# MB9BF51xN register map
File version: 1.8
CPU: 
Registers are 8-bit, read-write, reset 0x0 unless marked. A register's access mark holds for its fields unless they carry their own. Offsets are from the block's base; [hi:lo] are bit positions; {n}, {i} and the like mark numbered series.

## GPIO — General-purpose I/O ports
Base 0x40033000
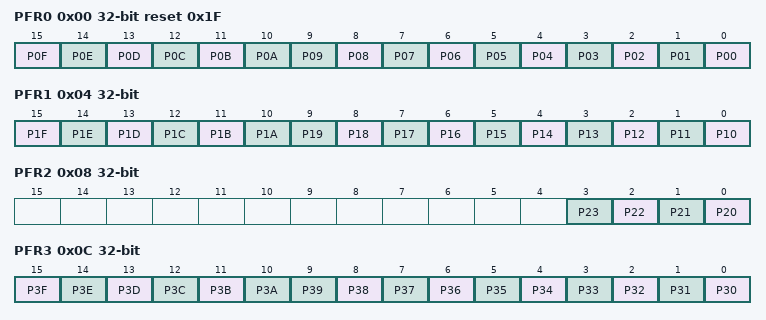
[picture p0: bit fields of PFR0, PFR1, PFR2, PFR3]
0x00 PFR0 32-bit reset 0x1F — Port function setting register 0
  [15] P0F — Bit15 of PFR0
  [14] P0E — Bit14 of PFR0
  [13] P0D — Bit13 of PFR0
  [12] P0C — Bit12 of PFR0
  [11] P0B — Bit11 of PFR0
  [10] P0A — Bit10 of PFR0
  [n] P{n:02} (n=0..9) — Bit{n} of PFR0
0x04 PFR1 32-bit — Port function setting register 1
  [15] P1F — Bit15 of PFR1
  [14] P1E — Bit14 of PFR1
  [13] P1D — Bit13 of PFR1
  [12] P1C — Bit12 of PFR1
  [11] P1B — Bit11 of PFR1
  [10] P1A — Bit10 of PFR1
  [n-10] P{n} (n=10..19) — Bit{n-10} of PFR1
0x08 PFR2 32-bit — Port function setting register 2
  [n-20] P{n} (n=20..23) — Bit{n-20} of PFR2
0x0C PFR3 32-bit — Port function setting register 3
  [15] P3F — Bit15 of PFR3
  [14] P3E — Bit14 of PFR3
  [13] P3D — Bit13 of PFR3
  [12] P3C — Bit12 of PFR3
  [11] P3B — Bit11 of PFR3
  [10] P3A — Bit10 of PFR3
  [n-30] P{n} (n=30..39) — Bit{n-30} of PFR3
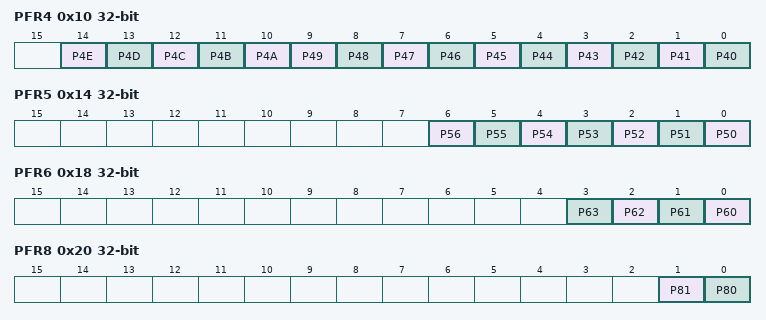
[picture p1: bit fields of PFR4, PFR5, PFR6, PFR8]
0x10 PFR4 32-bit — Port function setting register 4
  [14] P4E — Bit14 of PFR4
  [13] P4D — Bit13 of PFR4
  [12] P4C — Bit12 of PFR4
  [11] P4B — Bit11 of PFR4
  [10] P4A — Bit10 of PFR4
  [n-40] P{n} (n=40..49) — Bit{n-40} of PFR4
0x14 PFR5 32-bit — Port function setting register 5
  [n-50] P{n} (n=50..56) — Bit{n-50} of PFR5
0x18 PFR6 32-bit — Port function setting register 6
  [n-60] P{n} (n=60..63) — Bit{n-60} of PFR6
0x20 PFR8 32-bit — Port function setting register 8
  [1] P81 — Bit1 of PFR8
  [0] P80 — Bit0 of PFR8
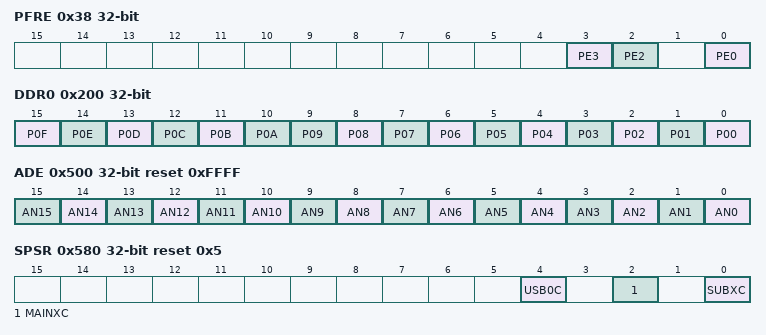
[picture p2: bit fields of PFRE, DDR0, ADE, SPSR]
0x38 PFRE 32-bit (reset mask 0xB) — Port function setting register E
  [3] PE3 — Bit3 of PFRE
  [2] PE2 — Bit2 of PFRE
  [0] PE0 — Bit0 of PFRE
{0x100+4i} PCR{i} 32-bit reset not defined (i=0..6) — Pull-up Setting Register {i}
0x120 PCR8 32-bit reset not defined — Pull-up Setting Register 8
0x138 PCRE 32-bit reset not defined — Pull-up Setting Register E
0x200 DDR0 32-bit — Port input/output direction setting register 0
  [15] P0F — Bit15 of DDR0
  [14] P0E — Bit14 of DDR0
  [13] P0D — Bit13 of DDR0
  [12] P0C — Bit12 of DDR0
  [11] P0B — Bit11 of DDR0
  [10] P0A — Bit10 of DDR0
  [n] P{n:02} (n=0..9) — Bit{n} of DDR0
{0x200+4i} DDR{i} 32-bit reset not defined (i=1..6) — Port input/output direction setting register {i}
0x220 DDR8 32-bit reset not defined — Port input/output direction setting register 8
0x238 DDRE 32-bit reset not defined — Port input/output direction setting register E
{0x300+4i} PDIR{i} 32-bit reset not defined (i=0..6) — Port input data register {i}
0x320 PDIR8 32-bit reset not defined — Port input data register 8
0x338 PDIRE 32-bit reset not defined — Port input data register E
{0x400+4i} PDOR{i} 32-bit reset not defined (i=0..6) — Port output data register {i}
0x420 PDOR8 32-bit reset not defined — Port output data register 8
0x438 PDORE 32-bit reset not defined — Port output data register E
0x500 ADE 32-bit reset 0xFFFF — Analog input setting register
  [n] AN{n} (n=0..15) — Bit{n} of ADE
0x580 SPSR 32-bit reset 0x5 — Special port setting register
  [4] USB0C — USBch0 pin setting bit
  [2] MAINXC — Main clock(oscillation) pin setting bit
  [0] SUBXC — Sub clock(oscillation) pin setting bit
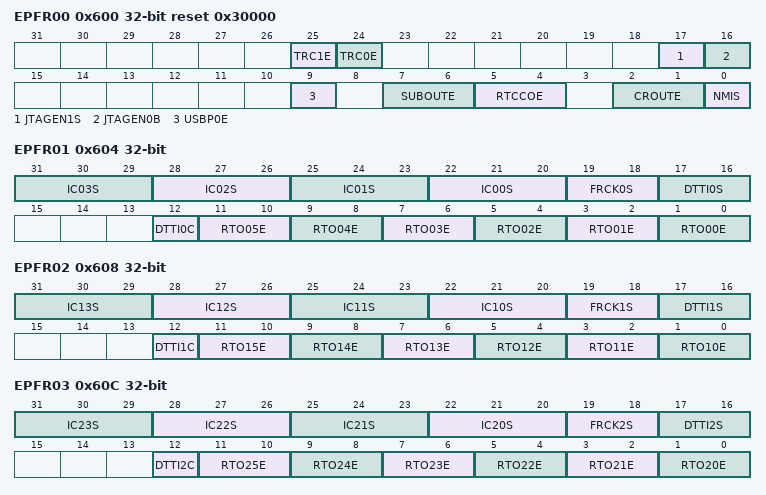
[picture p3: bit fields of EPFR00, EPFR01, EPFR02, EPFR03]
0x600 EPFR00 32-bit reset 0x30000 — Extended pin function setting register 00
  [25] TRC1E — TRACED function select bit1
  [24] TRC0E — TRACED function select bit0
  [17] JTAGEN1S — JTAG function select bit1
  [16] JTAGEN0B — JTAG function select bit0
  [9] USBP0E — USBch0 function select bit
  [7:6] SUBOUTE — Sub clock divide output function select bit
  [5:4] RTCCOE — RTC clock output select bit
  [2:1] CROUTE — Internal high-speed CR oscillation output function select bit
  [0] NMIS — NMIX function select bit
0x604 EPFR01 32-bit — Extended pin function setting register 01
  [3n+22:3n+20] IC{n:02}S (n=0..3) — IC{n:02} input select bit
  [19:18] FRCK0S — FRCK0 input select bit
  [17:16] DTTI0S — DTTIX0 input select bit
  [12] DTTI0C — DTTIX0 function select bit
  [2n+1:2n] RTO{n:02}E (n=0..5) — RTO{n:02}E output select bit
0x608 EPFR02 32-bit — Extended pin function setting register 02
  [3n-8:3n-10] IC{n}S (n=10..13) — IC{n} input select bit
  [19:18] FRCK1S — FRCK1 input select bit
  [17:16] DTTI1S — DTTIX1 input select bit
  [12] DTTI1C — DTTIX1 function select bit
  [2n-19:2n-20] RTO{n}E (n=10..15) — RTO{n}E output select bit
0x60C EPFR03 32-bit — Extended pin function setting register 03
  [3n-38:3n-40] IC{n}S (n=20..23) — IC{n} input select bit
  [19:18] FRCK2S — FRCK2 input select bit
  [17:16] DTTI2S — DTTIX2 input select bit
  [12] DTTI2C — DTTIX2 function select bit
  [2n-39:2n-40] RTO{n}E (n=20..25) — RTO{n}E output select bit
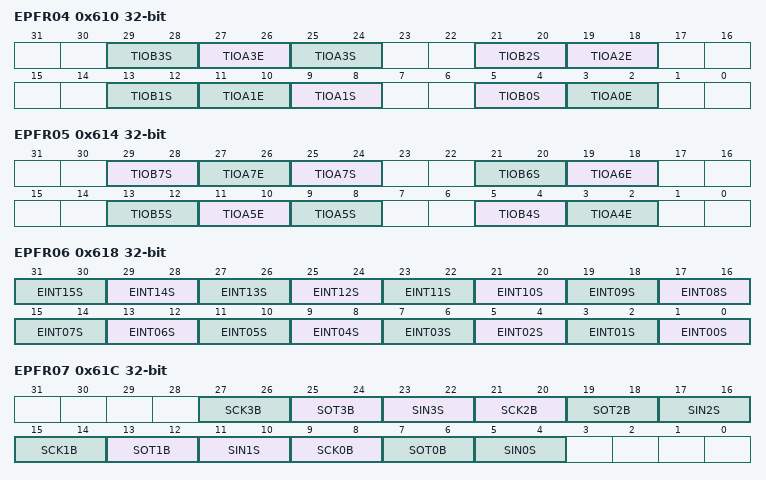
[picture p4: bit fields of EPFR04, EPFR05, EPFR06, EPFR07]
0x610 EPFR04 32-bit — Extended pin function setting register 04
  [8n+5:8n+4] TIOB{n}S (n=0..3) — TIOB{n} input select bit
  [27:26] TIOA3E — TIOA3E output select bit
  [25:24] TIOA3S — TIOA3 input select bit
  [19:18] TIOA2E — TIOA2 output select bit
  [11:10] TIOA1E — TIOA1E output select bit
  [9:8] TIOA1S — TIOA1 input select bit
  [3:2] TIOA0E — TIOA0 output select bit
0x614 EPFR05 32-bit — Extended pin function setting register 05
  [29:28] TIOB7S — TIOB7 input select Bit
  [27:26] TIOA7E — TIOA7E output select bit
  [25:24] TIOA7S — TIOA7 input select bit
  [21:20] TIOB6S — TIOB6 input select bit
  [19:18] TIOA6E — TIOA6 output select bit
  [13:12] TIOB5S — TIOB5 input select bit
  [11:10] TIOA5E — TIOA5E output select bit
  [9:8] TIOA5S — TIOA5 input select bit
  [5:4] TIOB4S — TIOB4 input select bit
  [3:2] TIOA4E — TIOA4 output select bit
0x618 EPFR06 32-bit — Extended pin function setting register 06
  [2n+1:2n] EINT{n:02}S (n=0..15) — External interrupt {n} input select bit
0x61C EPFR07 32-bit — Extended pin function setting register 07
  [6n+9:6n+8] SCK{n}B (n=0..3) — SCK{n} input/output select bit
  [25:24] SOT3B — SOT3B input/output select bit
  [6n+5:6n+4] SIN{n}S (n=0..3) — SIN{n}S input select bit
  [19:18] SOT2B — SOT2B input/output select bit
  [13:12] SOT1B — SCK1B input/output select bit
  [7:6] SOT0B — SOT0B input/output select bit
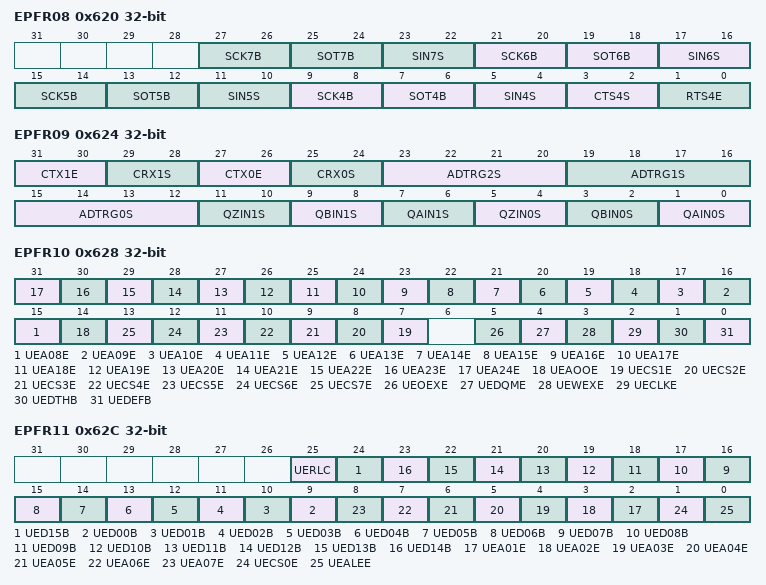
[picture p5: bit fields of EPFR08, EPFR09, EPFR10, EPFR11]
0x620 EPFR08 32-bit — Extended pin function setting register 08
  [6n-15:6n-16] SCK{n}B (n=4..7) — SCK{n} input/output select bit
  [6n-17:6n-18] SOT{n}B (n=4..7) — SOT{n}B input/output select bit
  [6n-19:6n-20] SIN{n}S (n=4..7) — SIN{n}S input select bit
  [3:2] CTS4S — CTS4S input select bit
  [1:0] RTS4E — RTS4E output select bit
0x624 EPFR09 32-bit — Extended pin function setting register 09
  [31:30] CTX1E — CAN TX1 Output Select bits
  [29:28] CRX1S — CAN RX1 Input Select bits
  [27:26] CTX0E — CAN TX0 Output Select bits
  [25:24] CRX0S — CAN RX0 Input Select bits
  [23:20] ADTRG2S — ADTRG2 input select bit
  [19:16] ADTRG1S — ADTRG1 input select bit
  [15:12] ADTRG0S — ADTRG0 input select bit
  [11:10] QZIN1S — QZIN1S input select bit
  [9:8] QBIN1S — QBIN1S input select bit
  [7:6] QAIN1S — QAIN1S input select bit
  [5:4] QZIN0S — QZIN0S input select bit
  [3:2] QBIN0S — QBIN0S input select bit
  [1:0] QAIN0S — QAIN0S input select bit
0x628 EPFR10 32-bit — Extended pin function setting register 10
  [n+7] UEA{n:02}E (n=8..24) — UEA{n:02}E output select bit
  [14] UEAOOE — UEAOOE output select bit
  [n+6] UECS{n}E (n=1..7) — UECS{n}E output select bit
  [5] UEOEXE — UEOEXE output select bit
  [4] UEDQME — UEDQME output select bit
  [3] UEWEXE — UEWEXE output select bit
  [2] UECLKE — UECLKE output select bit
  [1] UEDTHB — UEDTHB input/output select bit
  [0] UEDEFB — UEDEFB input/output select bit
0x62C EPFR11 32-bit — Extended pin function setting register 11
  [25] UERLC — UERLC relocation select bit
  [24] UED15B — UED15B input/output select bit
  [n+9] UED{n:02}B (n=0..14) — UED{n:02}B output select bit
  [n+1] UEA{n:02}E (n=1..7) — UEA{n:02}E output select bit
  [1] UECS0E — UECS0E output select bit
  [0] UEALEE — UEALEE output select bit
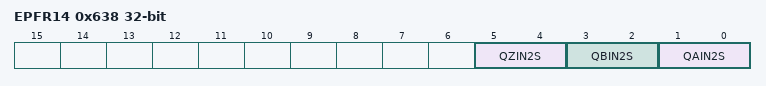
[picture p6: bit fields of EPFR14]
0x638 EPFR14 32-bit — Extended pin function setting register 14
  [5:4] QZIN2S — QDU-ch.2 ZIN Input Pin bits
  [3:2] QBIN2S — QDU-ch.2 BIN Input Pin bits
  [1:0] QAIN2S — QDU-ch.2 AIN Input Pin bits
{0x700+4i} PZR{i} 32-bit reset not defined (i=0..6) — Port Pseudo Open Drain Setting Register {i}
0x720 PZR8 32-bit reset not defined — Port Pseudo Open Drain Setting Register 8
0x738 PZRE 32-bit reset not defined — Port Pseudo Open Drain Setting Register E
